# N32H7xx register map
Vendor: Nationstech Ltd.; File version: 1.0
Registers are 32-bit, read-write, reset 0x0 unless marked. A register's access mark holds for its fields unless they carry their own. Offsets are from the block's base; [hi:lo] are bit positions; {n}, {i} and the like mark numbered series; 'fields as' and 'values as' point back to an identical list.

## PWR — Power Control
Base 0x58031000
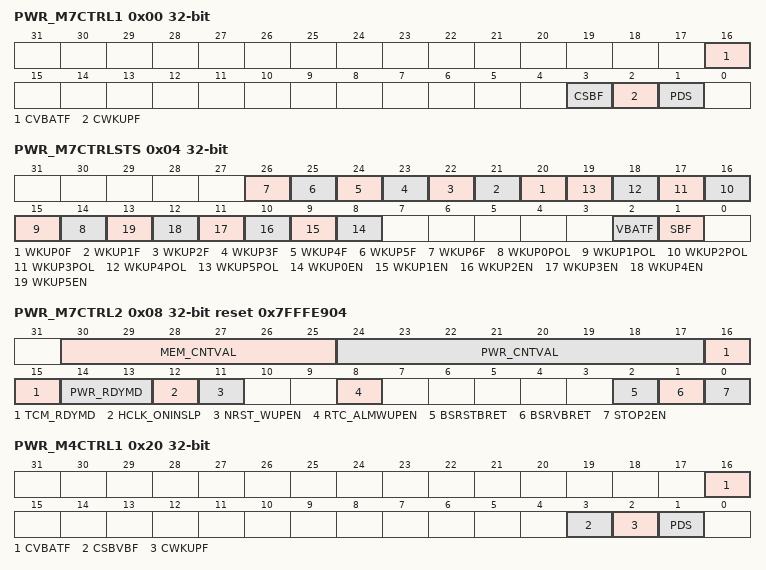
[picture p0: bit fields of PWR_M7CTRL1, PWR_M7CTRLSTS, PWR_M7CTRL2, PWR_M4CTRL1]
0x00 PWR_M7CTRL1 — Power Control Register
  [16] CVBATF, [3] CSBF, [2] CWKUPF, [1] PDS
0x04 PWR_M7CTRLSTS — Power Control/Status Register
  [n+20] WKUP{n}F (n=0..6), [n+14] WKUP{n}POL (n=0..5), [n+8] WKUP{n}EN (n=0..5), [2] VBATF, [1] SBF
0x08 PWR_M7CTRL2 reset 0x7FFFE904 — Power Control Register2
  [30:25] MEM_CNTVAL, [24:17] PWR_CNTVAL, [16:15] TCM_RDYMD, [14:13] PWR_RDYMD, [12] HCLK_ONINSLP, [11] NRST_WUPEN, [8] RTC_ALMWUPEN, [2] BSRSTBRET, [1] BSRVBRET, [0] STOP2EN
0x20 PWR_M4CTRL1 — Power Control Register
  [16] CVBATF, [3] CSBVBF, [2] CWKUPF, [1] PDS
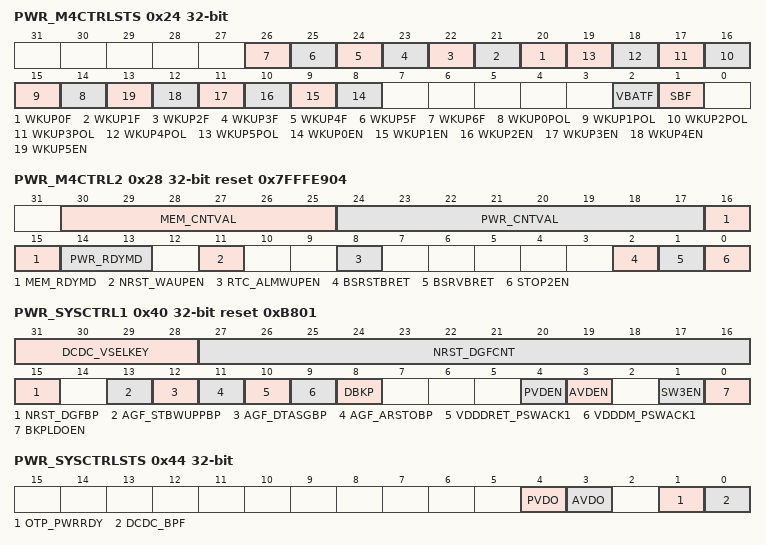
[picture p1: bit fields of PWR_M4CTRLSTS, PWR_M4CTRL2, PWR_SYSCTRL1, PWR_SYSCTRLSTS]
0x24 PWR_M4CTRLSTS — Power Control/Status Register
  fields as PWR_M7CTRLSTS
0x28 PWR_M4CTRL2 reset 0x7FFFE904 — Power Control Register2
  [30:25] MEM_CNTVAL, [24:17] PWR_CNTVAL, [16:15] MEM_RDYMD, [14:13] PWR_RDYMD, [11] NRST_WAUPEN, [8] RTC_ALMWUPEN, [2] BSRSTBRET, [1] BSRVBRET, [0] STOP2EN
0x40 PWR_SYSCTRL1 reset 0xB801 — System Power Control Register
  [31:28] DCDC_VSELKEY, [27:16] NRST_DGFCNT, [15] NRST_DGFBP, [13] AGF_STBWUPPBP, [12] AGF_DTASGBP, [11] AGF_ARSTOBP, [10] VDDDRET_PSWACK1, [9] VDDDM_PSWACK1, [8] DBKP, [4] PVDEN, [3] AVDEN, [1] SW3EN, [0] BKPLDOEN
0x44 PWR_SYSCTRLSTS ro — Power Control/Status Register
  [4] PVDO, [3] AVDO, [1] OTP_PWRRDY, [0] DCDC_BPF
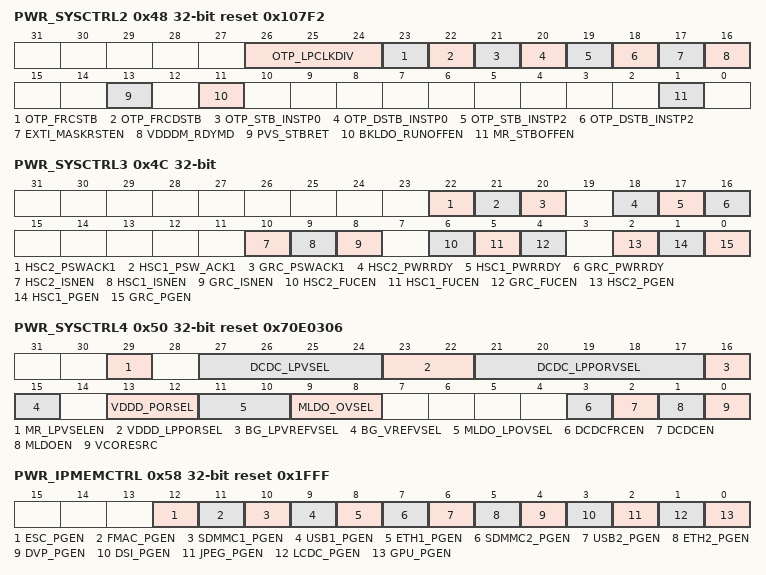
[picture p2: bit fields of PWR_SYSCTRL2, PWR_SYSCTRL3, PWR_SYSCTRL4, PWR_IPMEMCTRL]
0x48 PWR_SYSCTRL2 reset 0x107F2 — Power Control Register 2
  [26:24] OTP_LPCLKDIV, [23] OTP_FRCSTB, [22] OTP_FRCDSTB, [21] OTP_STB_INSTP0, [20] OTP_DSTB_INSTP0, [19] OTP_STB_INSTP2, [18] OTP_DSTB_INSTP2, [17] EXTI_MASKRSTEN, [16] VDDDM_RDYMD, [13] PVS_STBRET, [11] BKLDO_RUNOFFEN, [1] MR_STBOFFEN
0x4C PWR_SYSCTRL3 — Power Control Register 3
  [22] HSC2_PSWACK1, [21] HSC1_PSW_ACK1, [20] GRC_PSWACK1, [18] HSC2_PWRRDY, [17] HSC1_PWRRDY, [16] GRC_PWRRDY, [10] HSC2_ISNEN, [9] HSC1_ISNEN, [8] GRC_ISNEN, [6] HSC2_FUCEN, [5] HSC1_FUCEN, [4] GRC_FUCEN, [2] HSC2_PGEN, [1] HSC1_PGEN, [0] GRC_PGEN
0x50 PWR_SYSCTRL4 reset 0x70E0306 — System Power Control Register 4
  [29] MR_LPVSELEN, [27:24] DCDC_LPVSEL, [23:22] VDDD_LPPORSEL, [21:17] DCDC_LPPORVSEL, [16] BG_LPVREFVSEL, [15] BG_VREFVSEL, [13:12] VDDD_PORSEL, [11:10] MLDO_LPOVSEL, [9:8] MLDO_OVSEL, [3] DCDCFRCEN, [2] DCDCEN, [1] MLDOEN, [0] VCORESRC
0x58 PWR_IPMEMCTRL reset 0x1FFF — IP memory pwer gate control
  [12] ESC_PGEN, [11] FMAC_PGEN, [10] SDMMC1_PGEN, [9] USB1_PGEN, [8] ETH1_PGEN, [7] SDMMC2_PGEN, [6] USB2_PGEN, [5] ETH2_PGEN, [4] DVP_PGEN, [3] DSI_PGEN, [2] JPEG_PGEN, [1] LCDC_PGEN, [0] GPU_PGEN
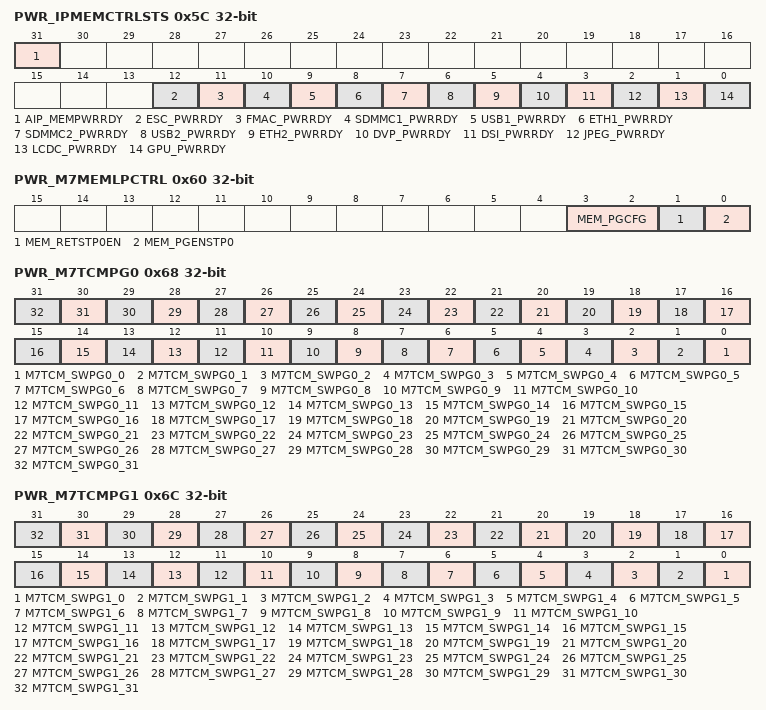
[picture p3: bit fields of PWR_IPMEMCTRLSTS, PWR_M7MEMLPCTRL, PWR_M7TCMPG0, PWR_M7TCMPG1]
0x5C PWR_IPMEMCTRLSTS ro — IP memory pwer status register
  [31] AIP_MEMPWRRDY, [12] ESC_PWRRDY, [11] FMAC_PWRRDY, [10] SDMMC1_PWRRDY, [9] USB1_PWRRDY, [8] ETH1_PWRRDY, [7] SDMMC2_PWRRDY, [6] USB2_PWRRDY, [5] ETH2_PWRRDY, [4] DVP_PWRRDY, [3] DSI_PWRRDY, [2] JPEG_PWRRDY, [1] LCDC_PWRRDY, [0] GPU_PWRRDY
0x60 PWR_M7MEMLPCTRL — CM7 Memory Low power control register
  [3:2] MEM_PGCFG, [1] MEM_RETSTP0EN, [0] MEM_PGENSTP0
0x64 PWR_M7MEMLPSTS — CM7 Memory low power status register
  [31] TCMRDY
0x68 PWR_M7TCMPG0 — CM7 TCM bank
  [n] M7TCM_SWPG0_{n} (n=0..31)
0x6C PWR_M7TCMPG1 — CM7 TCM PG software control register
  [n] M7TCM_SWPG1_{n} (n=0..31)
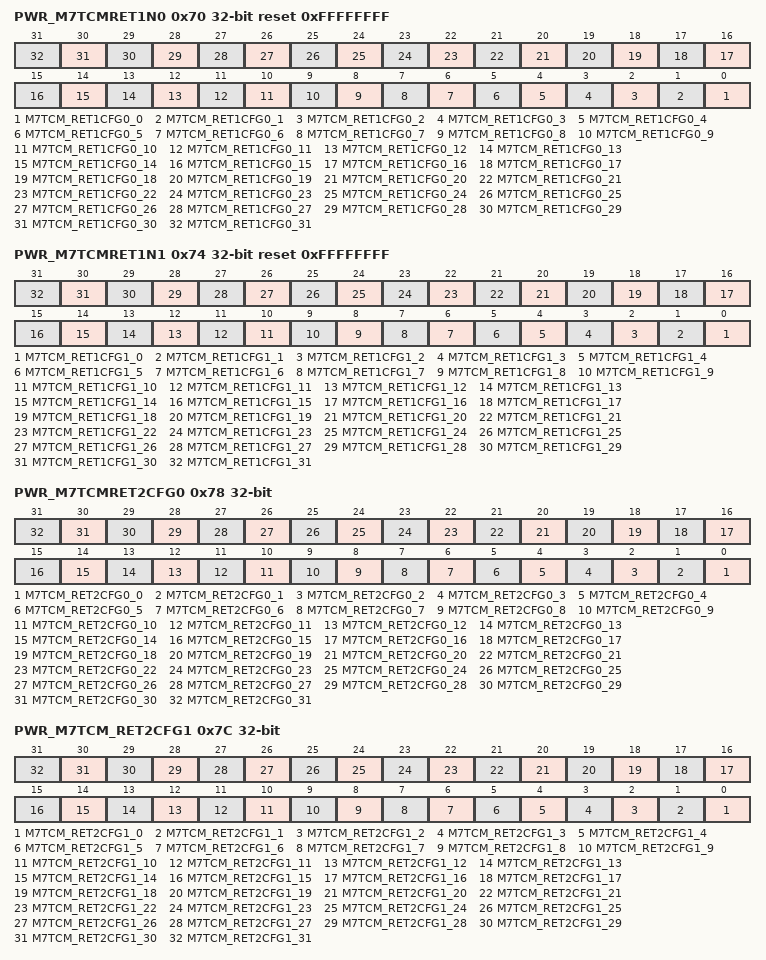
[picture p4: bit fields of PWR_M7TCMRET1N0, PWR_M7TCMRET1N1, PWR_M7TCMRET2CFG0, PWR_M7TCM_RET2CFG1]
0x70 PWR_M7TCMRET1N0 reset 0xFFFFFFFF — CM7 TCM bank
  [n] M7TCM_RET1CFG0_{n} (n=0..31)
0x74 PWR_M7TCMRET1N1 reset 0xFFFFFFFF — CM7 TCM bank
  [n] M7TCM_RET1CFG1_{n} (n=0..31)
0x78 PWR_M7TCMRET2CFG0 — CM7 TCM bank
  [n] M7TCM_RET2CFG0_{n} (n=0..31)
0x7C PWR_M7TCM_RET2CFG1 — CM7 TCM bank
  [n] M7TCM_RET2CFG1_{n} (n=0..31)
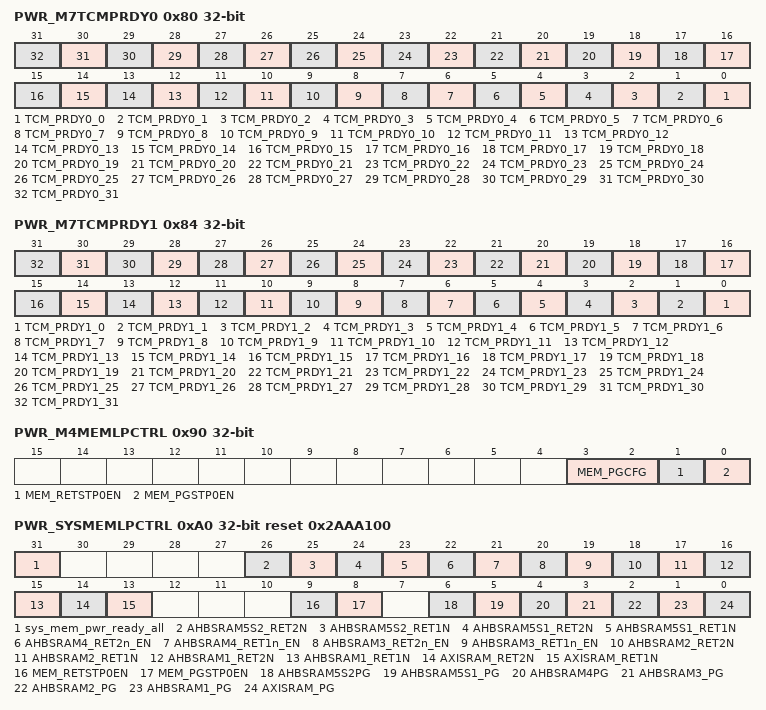
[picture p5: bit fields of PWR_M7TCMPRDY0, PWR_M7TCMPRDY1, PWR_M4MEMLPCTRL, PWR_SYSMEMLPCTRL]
0x80 PWR_M7TCMPRDY0 ro — Inverse of CM7 TCM bank
  [n] TCM_PRDY0_{n} (n=0..31)
0x84 PWR_M7TCMPRDY1 ro — Inverse of CM7 TCM bank
  [n] TCM_PRDY1_{n} (n=0..31)
0x90 PWR_M4MEMLPCTRL — CM4 Memory low power control register
  [3:2] MEM_PGCFG, [1] MEM_RETSTP0EN, [0] MEM_PGSTP0EN
0xA0 PWR_SYSMEMLPCTRL reset 0x2AAA100 — Power Control Register 2
  [31] sys_mem_pwr_ready_all, [26] AHBSRAM5S2_RET2N, [25] AHBSRAM5S2_RET1N, [24] AHBSRAM5S1_RET2N, [23] AHBSRAM5S1_RET1N, [22] AHBSRAM4_RET2n_EN, [21] AHBSRAM4_RET1n_EN, [20] AHBSRAM3_RET2n_EN, [19] AHBSRAM3_RET1n_EN, [18] AHBSRAM2_RET2N, [17] AHBSRAM2_RET1N, [16] AHBSRAM1_RET2N, [15] AHBSRAM1_RET1N, [14] AXISRAM_RET2N, [13] AXISRAM_RET1N, [9] MEM_RETSTP0EN, [8] MEM_PGSTP0EN, [6] AHBSRAM5S2PG, [5] AHBSRAM5S1_PG, [4] AHBSRAM4PG, [3] AHBSRAM3_PG, [2] AHBSRAM2_PG, [1] AHBSRAM1_PG, [0] AXISRAM_PG
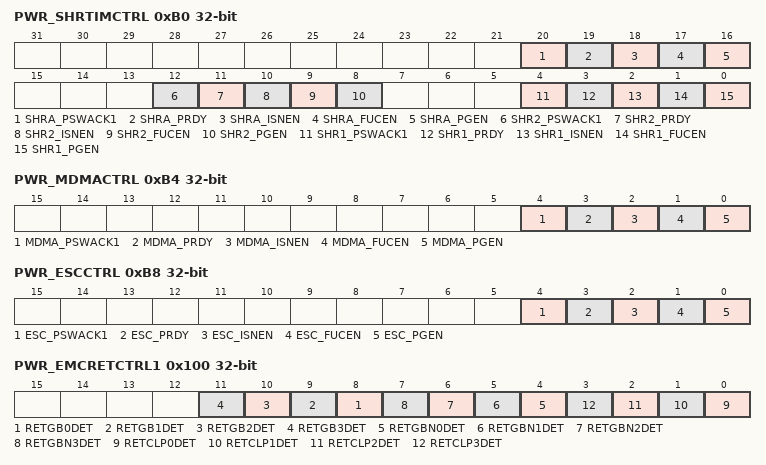
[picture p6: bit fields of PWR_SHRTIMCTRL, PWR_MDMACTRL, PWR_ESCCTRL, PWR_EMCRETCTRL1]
0xB0 PWR_SHRTIMCTRL — SHRTIMER Power Contorl Register
  [20] SHRA_PSWACK1, [19] SHRA_PRDY, [18] SHRA_ISNEN, [17] SHRA_FUCEN, [16] SHRA_PGEN, [12] SHR2_PSWACK1, [11] SHR2_PRDY, [10] SHR2_ISNEN, [9] SHR2_FUCEN, [8] SHR2_PGEN, [4] SHR1_PSWACK1, [3] SHR1_PRDY, [2] SHR1_ISNEN, [1] SHR1_FUCEN, [0] SHR1_PGEN
0xB4 PWR_MDMACTRL — MDMA Power Contorl Register
  [4] MDMA_PSWACK1, [3] MDMA_PRDY, [2] MDMA_ISNEN, [1] MDMA_FUCEN, [0] MDMA_PGEN
0xB8 PWR_ESCCTRL — ETHCAT Power Contorl Register
  [4] ESC_PSWACK1, [3] ESC_PRDY, [2] ESC_ISNEN, [1] ESC_FUCEN, [0] ESC_PGEN
0x100 PWR_EMCRETCTRL1 — EMC CONTROL REGISTER for EMC sets
  [n+8] RETGB{n}DET (n=0..3), [n+4] RETGBN{n}DET (n=0..3), [n] RETCLP{n}DET (n=0..3)
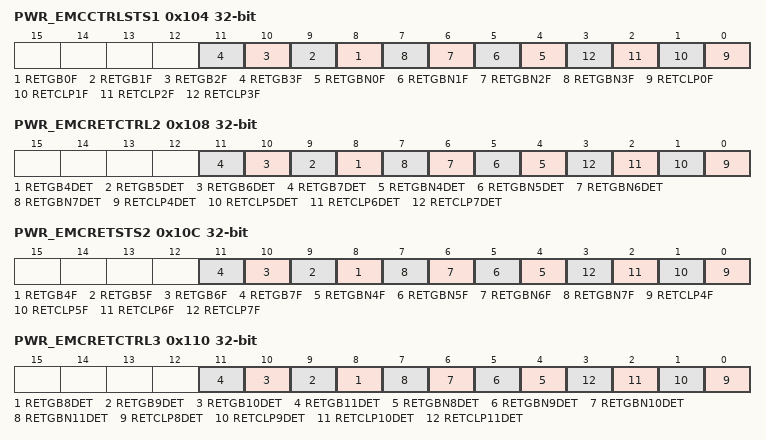
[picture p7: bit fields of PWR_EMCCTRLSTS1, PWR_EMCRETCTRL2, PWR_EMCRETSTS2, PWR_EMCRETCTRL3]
0x104 PWR_EMCCTRLSTS1 ro — EMC Flag REGISTER for EMC sets
  [n+8] RETGB{n}F (n=0..3), [n+4] RETGBN{n}F (n=0..3), [n] RETCLP{n}F (n=0..3)
0x108 PWR_EMCRETCTRL2 — EMC CONTROL REGISTER for EMC sets
  [n+4] RETGB{n}DET (n=4..7), [n] RETGBN{n}DET (n=4..7), [n-4] RETCLP{n}DET (n=4..7)
0x10C PWR_EMCRETSTS2 ro — EMC Flag REGISTER for EMC sets
  [n+4] RETGB{n}F (n=4..7), [n] RETGBN{n}F (n=4..7), [n-4] RETCLP{n}F (n=4..7)
0x110 PWR_EMCRETCTRL3 — EMC CONTROL REGISTER for EMC sets
  [n] RETGB{n}DET (n=8..11), [n-4] RETGBN{n}DET (n=8..11), [n-8] RETCLP{n}DET (n=8..11)
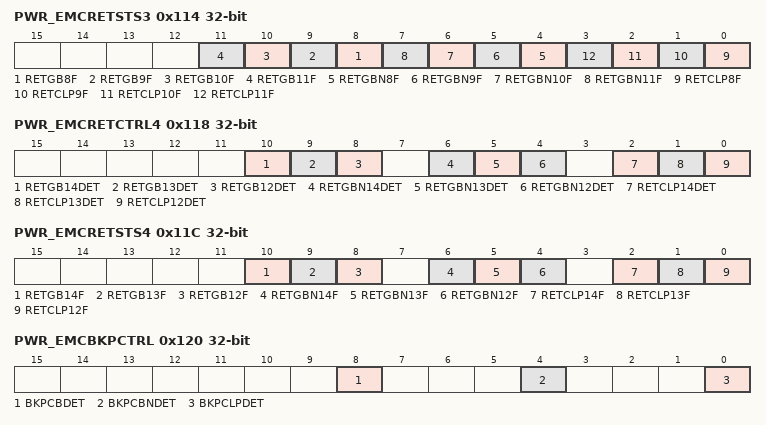
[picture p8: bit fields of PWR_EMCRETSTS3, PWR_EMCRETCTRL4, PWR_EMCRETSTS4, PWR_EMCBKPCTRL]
0x114 PWR_EMCRETSTS3 ro — EMC Flag REGISTER for EMC sets
  [n] RETGB{n}F (n=8..11), [n-4] RETGBN{n}F (n=8..11), [n-8] RETCLP{n}F (n=8..11)
0x118 PWR_EMCRETCTRL4 — EMC CONTROL REGISTER for EMC sets
  [10] RETGB14DET, [9] RETGB13DET, [8] RETGB12DET, [6] RETGBN14DET, [5] RETGBN13DET, [4] RETGBN12DET, [2] RETCLP14DET, [1] RETCLP13DET, [0] RETCLP12DET
0x11C PWR_EMCRETSTS4 ro — EMC Flag REGISTER for EMC sets
  [10] RETGB14F, [9] RETGB13F, [8] RETGB12F, [6] RETGBN14F, [5] RETGBN13F, [4] RETGBN12F, [2] RETCLP14F, [1] RETCLP13F, [0] RETCLP12F
0x120 PWR_EMCBKPCTRL — EMC CONTROL REGISTER for EMC set in BKP domain
  [8] BKPCBDET, [4] BKPCBNDET, [0] BKPCLPDET
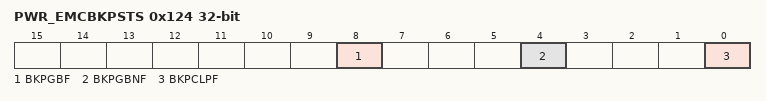
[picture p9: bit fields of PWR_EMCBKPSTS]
0x124 PWR_EMCBKPSTS ro — EMC flag for EMC set in BKP domain
  [8] BKPGBF, [4] BKPGBNF, [0] BKPCLPF
